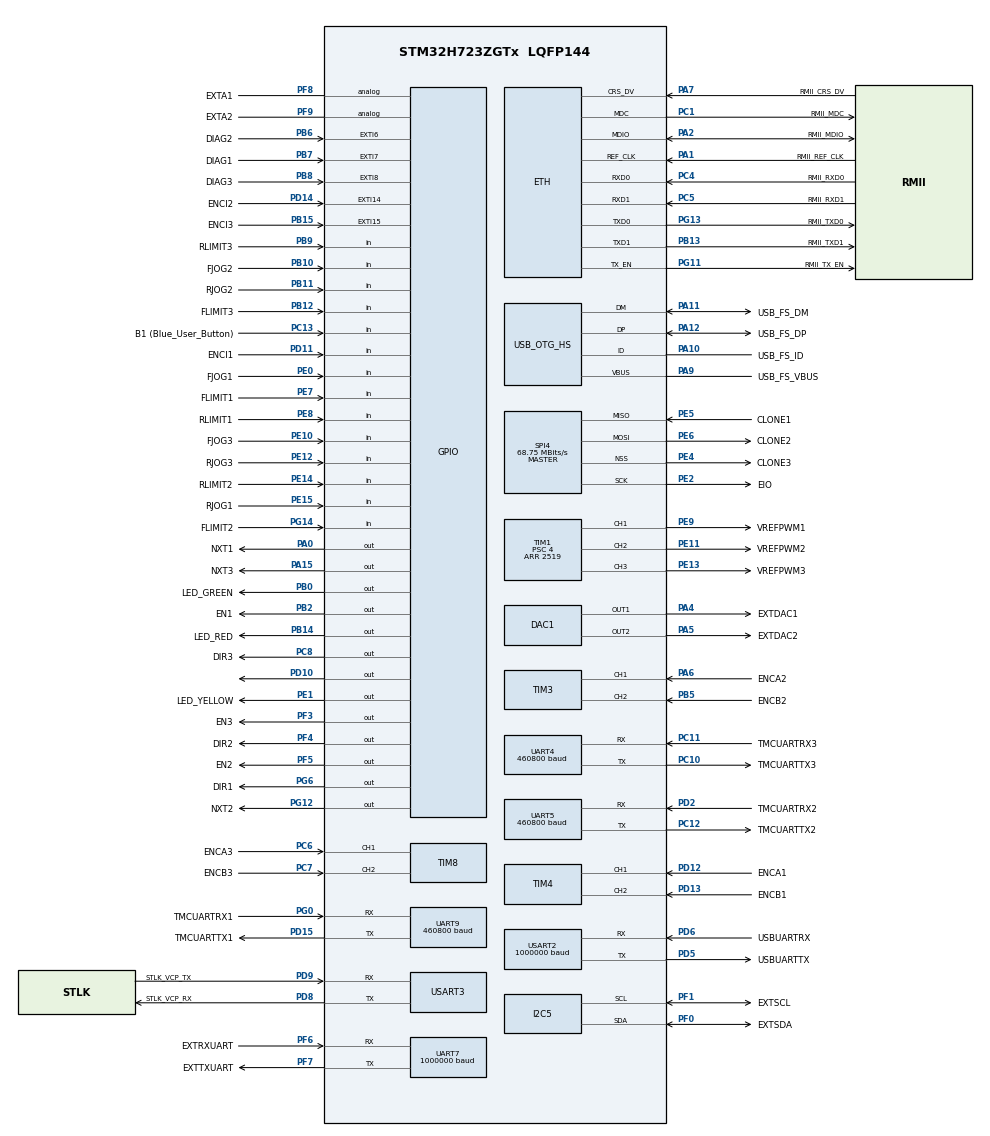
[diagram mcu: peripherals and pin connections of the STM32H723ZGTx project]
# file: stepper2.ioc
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DAC1.DAC_Channel-DAC_OUT1=DAC_CHANNEL_1
DAC1.DAC_Channel-DAC_OUT2=DAC_CHANNEL_2
Dma.Request0=USART2_RX
Dma.Request1=UART9_RX
Dma.Request2=UART5_RX
Dma.Request3=UART4_RX
Dma.UART4_RX.3.Direction=DMA_PERIPH_TO_MEMORY
Dma.UART4_RX.3.EventEnable=DISABLE
Dma.UART4_RX.3.FIFOMode=DMA_FIFOMODE_DISABLE
Dma.UART4_RX.3.Instance=DMA1_Stream3
Dma.UART4_RX.3.MemDataAlignment=DMA_MDATAALIGN_BYTE
Dma.UART4_RX.3.MemInc=DMA_MINC_ENABLE
Dma.UART4_RX.3.Mode=DMA_CIRCULAR
Dma.UART4_RX.3.PeriphDataAlignment=DMA_PDATAALIGN_BYTE
Dma.UART4_RX.3.PeriphInc=DMA_PINC_DISABLE
Dma.UART4_RX.3.Polarity=HAL_DMAMUX_REQ_GEN_RISING
Dma.UART4_RX.3.Priority=DMA_PRIORITY_LOW
Dma.UART4_RX.3.RequestNumber=1
Dma.UART4_RX.3.SignalID=NONE
Dma.UART4_RX.3.SyncEnable=DISABLE
Dma.UART4_RX.3.SyncPolarity=HAL_DMAMUX_SYNC_NO_EVENT
Dma.UART4_RX.3.SyncRequestNumber=1
Dma.UART4_RX.3.SyncSignalID=NONE
Dma.UART5_RX.2.Direction=DMA_PERIPH_TO_MEMORY
Dma.UART5_RX.2.EventEnable=DISABLE
Dma.UART5_RX.2.FIFOMode=DMA_FIFOMODE_DISABLE
Dma.UART5_RX.2.Instance=DMA1_Stream2
Dma.UART5_RX.2.MemDataAlignment=DMA_MDATAALIGN_BYTE
Dma.UART5_RX.2.MemInc=DMA_MINC_ENABLE
Dma.UART5_RX.2.Mode=DMA_CIRCULAR
Dma.UART5_RX.2.PeriphDataAlignment=DMA_PDATAALIGN_BYTE
Dma.UART5_RX.2.PeriphInc=DMA_PINC_DISABLE
Dma.UART5_RX.2.Polarity=HAL_DMAMUX_REQ_GEN_RISING
Dma.UART5_RX.2.Priority=DMA_PRIORITY_LOW
Dma.UART5_RX.2.RequestNumber=1
Dma.UART5_RX.2.SignalID=NONE
Dma.UART5_RX.2.SyncEnable=DISABLE
Dma.UART5_RX.2.SyncPolarity=HAL_DMAMUX_SYNC_NO_EVENT
Dma.UART5_RX.2.SyncRequestNumber=1
Dma.UART5_RX.2.SyncSignalID=NONE
Dma.UART9_RX.1.Direction=DMA_PERIPH_TO_MEMORY
Dma.UART9_RX.1.EventEnable=DISABLE
Dma.UART9_RX.1.FIFOMode=DMA_FIFOMODE_DISABLE
Dma.UART9_RX.1.Instance=DMA1_Stream1
Dma.UART9_RX.1.MemDataAlignment=DMA_MDATAALIGN_BYTE
Dma.UART9_RX.1.MemInc=DMA_MINC_ENABLE
Dma.UART9_RX.1.Mode=DMA_CIRCULAR
Dma.UART9_RX.1.PeriphDataAlignment=DMA_PDATAALIGN_BYTE
Dma.UART9_RX.1.PeriphInc=DMA_PINC_DISABLE
Dma.UART9_RX.1.Polarity=HAL_DMAMUX_REQ_GEN_RISING
Dma.UART9_RX.1.Priority=DMA_PRIORITY_LOW
Dma.UART9_RX.1.RequestNumber=1
Dma.UART9_RX.1.SignalID=NONE
Dma.UART9_RX.1.SyncEnable=DISABLE
Dma.UART9_RX.1.SyncPolarity=HAL_DMAMUX_SYNC_NO_EVENT
Dma.UART9_RX.1.SyncRequestNumber=1
Dma.UART9_RX.1.SyncSignalID=NONE
Dma.USART2_RX.0.Direction=DMA_PERIPH_TO_MEMORY
Dma.USART2_RX.0.EventEnable=DISABLE
Dma.USART2_RX.0.FIFOMode=DMA_FIFOMODE_DISABLE
Dma.USART2_RX.0.Instance=DMA1_Stream0
Dma.USART2_RX.0.MemDataAlignment=DMA_MDATAALIGN_BYTE
Dma.USART2_RX.0.MemInc=DMA_MINC_ENABLE
Dma.USART2_RX.0.Mode=DMA_CIRCULAR
Dma.USART2_RX.0.PeriphDataAlignment=DMA_PDATAALIGN_BYTE
Dma.USART2_RX.0.PeriphInc=DMA_PINC_DISABLE
Dma.USART2_RX.0.Polarity=HAL_DMAMUX_REQ_GEN_RISING
Dma.USART2_RX.0.Priority=DMA_PRIORITY_LOW
Dma.USART2_RX.0.RequestNumber=1
Dma.USART2_RX.0.SignalID=NONE
Dma.USART2_RX.0.SyncEnable=DISABLE
Dma.USART2_RX.0.SyncPolarity=HAL_DMAMUX_SYNC_NO_EVENT
Dma.USART2_RX.0.SyncRequestNumber=1
Dma.USART2_RX.0.SyncSignalID=NONE
ETH.MediaInterface=HAL_ETH_RMII_MODE
I2C5.Timing=0x60404E72
Mcu.Family=STM32H7
Mcu.Name=STM32H723ZGTx
Mcu.Package=LQFP144
NVIC.DMA1_Stream0_IRQn=true\:0\:0\:false\:false\:true\:false\:true\:true
NVIC.DMA1_Stream1_IRQn=true\:0\:0\:false\:false\:true\:false\:true\:true
NVIC.DMA1_Stream2_IRQn=true\:0\:0\:false\:false\:true\:false\:true\:true
NVIC.DMA1_Stream3_IRQn=true\:0\:0\:false\:false\:true\:false\:true\:true
NVIC.PriorityGroup=NVIC_PRIORITYGROUP_4
NVIC.TIM6_DAC_IRQn=true\:4\:0\:true\:false\:true\:true\:true\:true
NVIC.TIM7_IRQn=true\:2\:0\:true\:false\:true\:true\:true\:true
PA0.GPIO_Label=NXT1
PA0.Signal=GPIO_Output
PA1.GPIO_Label=RMII_REF_CLK
PA1.Mode=RMII
PA1.Signal=ETH_REF_CLK
PA10.GPIO_Label=USB_FS_ID
PA10.Mode=OTG/Dual-Role-Device-FS
PA10.Signal=USB_OTG_HS_ID
PA11.GPIO_Label=USB_FS_DM
PA11.Mode=OTG/Dual-Role-Device-FS
PA11.Signal=USB_OTG_HS_DM
PA12.GPIO_Label=USB_FS_DP
PA12.Mode=OTG/Dual-Role-Device-FS
PA12.Signal=USB_OTG_HS_DP
PA13(JTMS/SWDIO).GPIO_Label=SWDIO
PA13(JTMS/SWDIO).Mode=Trace_Asynchronous_SW
PA13(JTMS/SWDIO).Signal=DEBUG_JTMS-SWDIO
PA14(JTCK/SWCLK).GPIO_Label=SWCLK
PA14(JTCK/SWCLK).Mode=Trace_Asynchronous_SW
PA14(JTCK/SWCLK).Signal=DEBUG_JTCK-SWCLK
PA15(JTDI).GPIO_Label=NXT3
PA15(JTDI).Signal=GPIO_Output
PA2.GPIO_Label=RMII_MDIO
PA2.Mode=RMII
PA2.Signal=ETH_MDIO
PA4.GPIO_Label=EXTDAC1
PA4.Signal=COMP_DAC11_group
PA5.GPIO_Label=EXTDAC2
PA5.Signal=COMP_DAC12_group
PA6.GPIO_Label=ENCA2
PA6.Signal=S_TIM3_CH1
PA7.GPIO_Label=RMII_CRS_DV
PA7.Mode=RMII
PA7.Signal=ETH_CRS_DV
PA9.GPIO_Label=USB_FS_VBUS
PA9.Mode=Activate_VBUS_FS
PA9.Signal=USB_OTG_HS_VBUS
PB0.GPIO_Label=LED_GREEN
PB0.Signal=GPIO_Output
PB10.GPIO_Label=FJOG2
PB10.GPIO_PuPd=GPIO_PULLUP
PB10.Signal=GPIO_Input
PB11.GPIO_Label=RJOG2
PB11.GPIO_PuPd=GPIO_PULLUP
PB11.Signal=GPIO_Input
PB12.GPIO_Label=FLIMIT3
PB12.Signal=GPIO_Input
PB13.GPIO_Label=RMII_TXD1
PB13.Mode=RMII
PB13.Signal=ETH_TXD1
PB14.GPIO_Label=LED_RED
PB14.Signal=GPIO_Output
PB15.GPIO_Label=ENCI3
PB15.Signal=GPXTI15
PB2.GPIO_Label=EN1
PB2.Signal=GPIO_Output
PB3(JTDO/TRACESWO).GPIO_Label=SWO
PB3(JTDO/TRACESWO).Mode=Trace_Asynchronous_SW
PB3(JTDO/TRACESWO).Signal=DEBUG_JTDO-SWO
PB5.GPIO_Label=ENCB2
PB5.Signal=S_TIM3_CH2
PB6.GPIO_Label=DIAG2
PB6.Signal=GPXTI6
PB7.GPIO_Label=DIAG1
PB7.Signal=GPXTI7
PB8.GPIO_Label=DIAG3
PB8.Signal=GPXTI8
PB9.GPIO_Label=RLIMIT3
PB9.Signal=GPIO_Input
PC1.GPIO_Label=RMII_MDC
PC1.Mode=RMII
PC1.Signal=ETH_MDC
PC10.GPIO_Label=TMCUARTTX3
PC10.Mode=Asynchronous
PC10.Signal=UART4_TX
PC11.GPIO_Label=TMCUARTRX3
PC11.Mode=Asynchronous
PC11.Signal=UART4_RX
PC12.GPIO_Label=TMCUARTTX2
PC12.Mode=Asynchronous
PC12.Signal=UART5_TX
PC13.GPIO_Label=B1 (Blue_User_Button)
PC13.Signal=GPIO_Input
PC14-OSC32_IN.Mode=LSE-External-Oscillator
PC14-OSC32_IN.Signal=RCC_OSC32_IN
PC15-OSC32_OUT.Mode=LSE-External-Oscillator
PC15-OSC32_OUT.Signal=RCC_OSC32_OUT
PC4.GPIO_Label=RMII_RXD0
PC4.Mode=RMII
PC4.Signal=ETH_RXD0
PC5.GPIO_Label=RMII_RXD1
PC5.Mode=RMII
PC5.Signal=ETH_RXD1
PC6.GPIO_Label=ENCA3
PC6.Signal=S_TIM8_CH1
PC7.GPIO_Label=ENCB3
PC7.Signal=S_TIM8_CH2
PC8.GPIO_Label=DIR3
PC8.Signal=GPIO_Output
PD10.Signal=GPIO_Output
PD11.GPIO_Label=ENCI1
PD11.Signal=GPIO_Input
PD12.GPIO_Label=ENCA1
PD12.Signal=S_TIM4_CH1
PD13.GPIO_Label=ENCB1
PD13.Signal=S_TIM4_CH2
PD14.GPIO_Label=ENCI2
PD14.Signal=GPXTI14
PD15.GPIO_Label=TMCUARTTX1
PD15.Mode=Asynchronous
PD15.Signal=UART9_TX
PD2.GPIO_Label=TMCUARTRX2
PD2.GPIO_PuPd=GPIO_NOPULL
PD2.Mode=Asynchronous
PD2.Signal=UART5_RX
PD5.GPIO_Label=USBUARTTX
PD5.Mode=Asynchronous
PD5.Signal=USART2_TX
PD6.GPIO_Label=USBUARTRX
PD6.Mode=Asynchronous
PD6.Signal=USART2_RX
PD8.GPIO_Label=STLK_VCP_RX
PD8.Mode=Asynchronous
PD8.Signal=USART3_TX
PD9.GPIO_Label=STLK_VCP_TX
PD9.Mode=Asynchronous
PD9.Signal=USART3_RX
PE0.GPIO_Label=FJOG1
PE0.GPIO_PuPd=GPIO_PULLUP
PE0.Signal=GPIO_Input
PE1.GPIO_Label=LED_YELLOW
PE1.Signal=GPIO_Output
PE10.GPIO_Label=FJOG3
PE10.GPIO_PuPd=GPIO_PULLUP
PE10.Signal=GPIO_Input
PE11.GPIO_Label=VREFPWM2
PE11.Signal=S_TIM1_CH2
PE12.GPIO_Label=RJOG3
PE12.GPIO_PuPd=GPIO_PULLUP
PE12.Signal=GPIO_Input
PE13.GPIO_Label=VREFPWM3
PE13.Signal=S_TIM1_CH3
PE14.GPIO_Label=RLIMIT2
PE14.Signal=GPIO_Input
PE15.GPIO_Label=RJOG1
PE15.GPIO_PuPd=GPIO_PULLUP
PE15.Signal=GPIO_Input
PE2.GPIO_Label=EIO
PE2.Mode=Full_Duplex_Master
PE2.Signal=SPI4_SCK
PE4.GPIO_Label=CLONE3
PE4.Mode=NSS_Signal_Hard_Output
PE4.Signal=SPI4_NSS
PE5.GPIO_Label=CLONE1
PE5.Mode=Full_Duplex_Master
PE5.Signal=SPI4_MISO
PE6.GPIO_Label=CLONE2
PE6.Mode=Full_Duplex_Master
PE6.Signal=SPI4_MOSI
PE7.GPIO_Label=FLIMIT1
PE7.Signal=GPIO_Input
PE8.GPIO_Label=RLIMIT1
PE8.Signal=GPIO_Input
PE9.GPIO_Label=VREFPWM1
PE9.Signal=S_TIM1_CH1
PF0.GPIO_Label=EXTSDA
PF0.Mode=I2C
PF0.Signal=I2C5_SDA
PF1.GPIO_Label=EXTSCL
PF1.Mode=I2C
PF1.Signal=I2C5_SCL
PF3.GPIO_Label=EN3
PF3.Signal=GPIO_Output
PF4.GPIO_Label=DIR2
PF4.Signal=GPIO_Output
PF5.GPIO_Label=EN2
PF5.Signal=GPIO_Output
PF6.GPIO_Label=EXTRXUART
PF6.Mode=Asynchronous
PF6.Signal=UART7_RX
PF7.GPIO_Label=EXTTXUART
PF7.Mode=Asynchronous
PF7.Signal=UART7_TX
PF8.GPIO_Label=EXTA1
PF8.Signal=GPIO_Analog
PF9.GPIO_Label=EXTA2
PF9.Signal=GPIO_Analog
PG0.GPIO_Label=TMCUARTRX1
PG0.Mode=Asynchronous
PG0.Signal=UART9_RX
PG11.GPIO_Label=RMII_TX_EN
PG11.Mode=RMII
PG11.Signal=ETH_TX_EN
PG12.GPIO_Label=NXT2
PG12.Signal=GPIO_Output
PG13.GPIO_Label=RMII_TXD0
PG13.Mode=RMII
PG13.Signal=ETH_TXD0
PG14.GPIO_Label=FLIMIT2
PG14.Signal=GPIO_Input
PG6.GPIO_Label=DIR1
PG6.Signal=GPIO_Output
PH0-OSC_IN.GPIO_Label=MCO
PH0-OSC_IN.Mode=HSE-External-Clock-Source
PH0-OSC_IN.Signal=RCC_OSC_IN
PH1-OSC_OUT.Signal=RCC_OSC_OUT
ProjectManager.HeapSize=0x200
ProjectManager.StackSize=0x400
ProjectManager.TargetToolchain=STM32CubeIDE
RCC.ADCFreq_Value=76000000
RCC.APB1Freq_Value=137500000
RCC.APB2Freq_Value=137500000
RCC.APB3Freq_Value=137500000
RCC.APB4Freq_Value=137500000
RCC.CortexFreq_Value=550000000
RCC.D1PPRE=RCC_APB3_DIV2
RCC.D2PPRE1=RCC_APB1_DIV2
RCC.D2PPRE2=RCC_APB2_DIV2
RCC.D3PPRE=RCC_APB4_DIV2
RCC.DIVM1=4
RCC.DIVM2=1
RCC.DIVN1=275
RCC.DIVN2=19
RCC.DIVP1=1
RCC.DIVQ1=4
RCC.HCLKFreq_Value=275000000
RCC.HPRE=RCC_HCLK_DIV2
RCC.HSE_VALUE=8000000
RCC.PLLFRACN=0
RCC.PLLSourceVirtual=RCC_PLLSOURCE_HSE
RCC.SYSCLKFreq_VALUE=550000000
RCC.SYSCLKSource=RCC_SYSCLKSOURCE_PLLCLK
RCC.USBCLockSelection=RCC_USBCLKSOURCE_HSI48
RCC.USBFreq_Value=48000000
SH.COMP_DAC11_group.0=DAC1_OUT1,DAC_OUT1
SH.COMP_DAC12_group.0=DAC1_OUT2,DAC_OUT2
SH.S_TIM1_CH1.0=TIM1_CH1,PWM Generation1 CH1
SH.S_TIM1_CH2.0=TIM1_CH2,PWM Generation2 CH2
SH.S_TIM1_CH3.0=TIM1_CH3,PWM Generation3 CH3
SH.S_TIM3_CH1.0=TIM3_CH1,Encoder_Interface
SH.S_TIM3_CH2.0=TIM3_CH2,Encoder_Interface
SH.S_TIM4_CH1.0=TIM4_CH1,Encoder_Interface
SH.S_TIM4_CH2.0=TIM4_CH2,Encoder_Interface
SH.S_TIM8_CH1.0=TIM8_CH1,Encoder_Interface
SH.S_TIM8_CH2.0=TIM8_CH2,Encoder_Interface
SPI4.CalculateBaudRate=68.75 MBits/s
SPI4.Direction=SPI_DIRECTION_2LINES
SPI4.Mode=SPI_MODE_MASTER
SPI4.VirtualNSS=VM_NSSHARD
SPI4.VirtualType=VM_MASTER
TIM1.AutoReloadPreload=TIM_AUTORELOAD_PRELOAD_ENABLE
TIM1.Channel-PWM\ Generation1\ CH1=TIM_CHANNEL_1
TIM1.Channel-PWM\ Generation2\ CH2=TIM_CHANNEL_2
TIM1.Channel-PWM\ Generation3\ CH3=TIM_CHANNEL_3
TIM1.Period=2519
TIM1.Prescaler=4
TIM24.Period=0xffffffff
TIM24.Prescaler=274
TIM3.EncoderMode=TIM_ENCODERMODE_TI12
TIM4.EncoderMode=TIM_ENCODERMODE_TI12
TIM6.AutoReloadPreload=TIM_AUTORELOAD_PRELOAD_DISABLE
TIM6.Period=999
TIM6.Prescaler=274
TIM7.AutoReloadPreload=TIM_AUTORELOAD_PRELOAD_DISABLE
TIM7.Period=1759
TIM8.EncoderMode=TIM_ENCODERMODE_TI12
UART4.BaudRate=460800
UART5.BaudRate=460800
UART7.BaudRate=1000000
UART9.BaudRate=460800
USART2.BaudRate=1000000
USART2.VirtualMode-Asynchronous=VM_ASYNC
USART3.VirtualMode-Asynchronous=VM_ASYNC
VP_TIM1_VS_ClockSourceINT.Mode=Internal
VP_TIM24_VS_ClockSourceINT.Mode=Internal
VP_TIM6_VS_ClockSourceINT.Mode=Enable_Timer
VP_TIM7_VS_ClockSourceINT.Mode=Enable_Timer
board=NUCLEO-H723ZG

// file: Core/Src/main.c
/* USER CODE BEGIN Header */
/**
  ******************************************************************************
  * @file           : main.c
  * @brief          : Main program body
  ******************************************************************************
  * @attention
  *
  * Copyright (c) 2023 STMicroelectronics.
  * All rights reserved.
  *
  * This software is licensed under terms that can be found in the LICENSE file
  * in the root directory of this software component.
  * If no LICENSE file comes with this software, it is provided AS-IS.
  *
  ******************************************************************************
  */
/* USER CODE END Header */
#include "main.h"
#include "string.h"

/* USER CODE BEGIN Includes */

#include "usr_main.hpp"
#include "handles.hpp"
/* USER CODE END Includes */

#if defined ( __ICCARM__ ) /*!< IAR Compiler */
#pragma location=0x30000000
ETH_DMADescTypeDef  DMARxDscrTab[ETH_RX_DESC_CNT]; /* Ethernet Rx DMA Descriptors */
#pragma location=0x30000200
ETH_DMADescTypeDef  DMATxDscrTab[ETH_TX_DESC_CNT]; /* Ethernet Tx DMA Descriptors */

#elif defined ( __CC_ARM )  /* MDK ARM Compiler */

__attribute__((at(0x30000000))) ETH_DMADescTypeDef  DMARxDscrTab[ETH_RX_DESC_CNT]; /* Ethernet Rx DMA Descriptors */
__attribute__((at(0x30000200))) ETH_DMADescTypeDef  DMATxDscrTab[ETH_TX_DESC_CNT]; /* Ethernet Tx DMA Descriptors */

#elif defined ( __GNUC__ ) /* GNU Compiler */
ETH_DMADescTypeDef DMARxDscrTab[ETH_RX_DESC_CNT] __attribute__((section(".RxDecripSection"))); /* Ethernet Rx DMA Descriptors */
ETH_DMADescTypeDef DMATxDscrTab[ETH_TX_DESC_CNT] __attribute__((section(".TxDecripSection")));   /* Ethernet Tx DMA Descriptors */

#endif

ETH_TxPacketConfig TxConfig;

DAC_HandleTypeDef hdac1;

ETH_HandleTypeDef heth;

I2C_HandleTypeDef hi2c5;

SPI_HandleTypeDef hspi4;

TIM_HandleTypeDef htim1;
TIM_HandleTypeDef htim3;
TIM_HandleTypeDef htim4;
TIM_HandleTypeDef htim6;
TIM_HandleTypeDef htim7;
TIM_HandleTypeDef htim8;
TIM_HandleTypeDef htim24;

UART_HandleTypeDef huart4;
UART_HandleTypeDef huart5;
UART_HandleTypeDef huart7;
UART_HandleTypeDef huart9;
UART_HandleTypeDef huart2;
UART_HandleTypeDef huart3;
DMA_HandleTypeDef hdma_uart4_rx;
DMA_HandleTypeDef hdma_uart5_rx;
DMA_HandleTypeDef hdma_uart9_rx;
DMA_HandleTypeDef hdma_usart2_rx;

void SystemClock_Config(void);
static void MX_GPIO_Init(void);
static void MX_DMA_Init(void);
static void MX_USART3_UART_Init(void);
static void MX_USB_OTG_HS_USB_Init(void);
static void MX_TIM1_Init(void);
static void MX_TIM3_Init(void);
static void MX_TIM4_Init(void);
static void MX_TIM8_Init(void);
static void MX_UART4_Init(void);
static void MX_UART5_Init(void);
static void MX_UART7_Init(void);
static void MX_USART2_UART_Init(void);
static void MX_DAC1_Init(void);
static void MX_I2C5_Init(void);
static void MX_SPI4_Init(void);
static void MX_UART9_Init(void);
static void MX_ETH_Init(void);
static void MX_TIM24_Init(void);
static void MX_TIM6_Init(void);
static void MX_TIM7_Init(void);

int main(void)
{

  /* MCU Configuration--------------------------------------------------------*/

  /* Reset of all peripherals, Initializes the Flash interface and the Systick. */
  HAL_Init();

  /* Configure the system clock */
  SystemClock_Config();

  /* Initialize all configured peripherals */
  MX_GPIO_Init();
  MX_DMA_Init();
  MX_USART3_UART_Init();
  MX_USB_OTG_HS_USB_Init();
  MX_TIM1_Init();
  MX_TIM3_Init();
  MX_TIM4_Init();
  MX_TIM8_Init();
  MX_UART4_Init();
  MX_UART5_Init();
  MX_UART7_Init();
  MX_USART2_UART_Init();
  MX_DAC1_Init();
  MX_I2C5_Init();
  MX_SPI4_Init();
  MX_UART9_Init();
  MX_ETH_Init();
  MX_TIM24_Init();
  MX_TIM6_Init();
  MX_TIM7_Init();

  /* Infinite loop */
  /* USER CODE BEGIN WHILE */
  usr_main();
    /* USER CODE END WHILE */

}

void SystemClock_Config(void)
{
  RCC_OscInitTypeDef RCC_OscInitStruct = {0};
  RCC_ClkInitTypeDef RCC_ClkInitStruct = {0};

  /** Supply configuration update enable
  */
  HAL_PWREx_ConfigSupply(PWR_LDO_SUPPLY);

  /** Configure the main internal regulator output voltage
  */
  __HAL_PWR_VOLTAGESCALING_CONFIG(PWR_REGULATOR_VOLTAGE_SCALE0);

  while(!__HAL_PWR_GET_FLAG(PWR_FLAG_VOSRDY)) {}

  /** Initializes the RCC Oscillators according to the specified parameters
  * in the RCC_OscInitTypeDef structure.
  */
  RCC_OscInitStruct.OscillatorType = RCC_OSCILLATORTYPE_HSI48|RCC_OSCILLATORTYPE_HSE;
  RCC_OscInitStruct.HSEState = RCC_HSE_BYPASS;
  RCC_OscInitStruct.HSI48State = RCC_HSI48_ON;
  RCC_OscInitStruct.PLL.PLLState = RCC_PLL_ON;
  RCC_OscInitStruct.PLL.PLLSource = RCC_PLLSOURCE_HSE;
  RCC_OscInitStruct.PLL.PLLM = 4;
  RCC_OscInitStruct.PLL.PLLN = 275;
  RCC_OscInitStruct.PLL.PLLP = 1;
  RCC_OscInitStruct.PLL.PLLQ = 4;
  RCC_OscInitStruct.PLL.PLLR = 2;
  RCC_OscInitStruct.PLL.PLLRGE = RCC_PLL1VCIRANGE_1;
  RCC_OscInitStruct.PLL.PLLVCOSEL = RCC_PLL1VCOWIDE;
  RCC_OscInitStruct.PLL.PLLFRACN = 0;
  if (HAL_RCC_OscConfig(&RCC_OscInitStruct) != HAL_OK)
  {
    Error_Handler();
  }

  /** Initializes the CPU, AHB and APB buses clocks
  */
  RCC_ClkInitStruct.ClockType = RCC_CLOCKTYPE_HCLK|RCC_CLOCKTYPE_SYSCLK
                              |RCC_CLOCKTYPE_PCLK1|RCC_CLOCKTYPE_PCLK2
                              |RCC_CLOCKTYPE_D3PCLK1|RCC_CLOCKTYPE_D1PCLK1;
  RCC_ClkInitStruct.SYSCLKSource = RCC_SYSCLKSOURCE_PLLCLK;
  RCC_ClkInitStruct.SYSCLKDivider = RCC_SYSCLK_DIV1;
  RCC_ClkInitStruct.AHBCLKDivider = RCC_HCLK_DIV2;
  RCC_ClkInitStruct.APB3CLKDivider = RCC_APB3_DIV2;
  RCC_ClkInitStruct.APB1CLKDivider = RCC_APB1_DIV2;
  RCC_ClkInitStruct.APB2CLKDivider = RCC_APB2_DIV2;
  RCC_ClkInitStruct.APB4CLKDivider = RCC_APB4_DIV2;

  if (HAL_RCC_ClockConfig(&RCC_ClkInitStruct, FLASH_LATENCY_3) != HAL_OK)
  {
    Error_Handler();
  }
}

static void MX_DAC1_Init(void)
{

  DAC_ChannelConfTypeDef sConfig = {0};

  /** DAC Initialization
  */
  hdac1.Instance = DAC1;
  if (HAL_DAC_Init(&hdac1) != HAL_OK)
  {
    Error_Handler();
  }

  /** DAC channel OUT1 config
  */
  sConfig.DAC_SampleAndHold = DAC_SAMPLEANDHOLD_DISABLE;
  sConfig.DAC_Trigger = DAC_TRIGGER_NONE;
  sConfig.DAC_OutputBuffer = DAC_OUTPUTBUFFER_ENABLE;
  sConfig.DAC_ConnectOnChipPeripheral = DAC_CHIPCONNECT_DISABLE;
  sConfig.DAC_UserTrimming = DAC_TRIMMING_FACTORY;
  if (HAL_DAC_ConfigChannel(&hdac1, &sConfig, DAC_CHANNEL_1) != HAL_OK)
  {
    Error_Handler();
  }

  /** DAC channel OUT2 config
  */
  if (HAL_DAC_ConfigChannel(&hdac1, &sConfig, DAC_CHANNEL_2) != HAL_OK)
  {
    Error_Handler();
  }

}

static void MX_ETH_Init(void)
{

   static uint8_t MACAddr[6];

  heth.Instance = ETH;
  MACAddr[0] = 0x00;
  MACAddr[1] = 0x80;
  MACAddr[2] = 0xE1;
  MACAddr[3] = 0x00;
  MACAddr[4] = 0x00;
  MACAddr[5] = 0x00;
  heth.Init.MACAddr = &MACAddr[0];
  heth.Init.MediaInterface = HAL_ETH_RMII_MODE;
  heth.Init.TxDesc = DMATxDscrTab;
  heth.Init.RxDesc = DMARxDscrTab;
  heth.Init.RxBuffLen = 1524;

  if (HAL_ETH_Init(&heth) != HAL_OK)
  {
    Error_Handler();
  }

  memset(&TxConfig, 0 , sizeof(ETH_TxPacketConfig));
  TxConfig.Attributes = ETH_TX_PACKETS_FEATURES_CSUM | ETH_TX_PACKETS_FEATURES_CRCPAD;
  TxConfig.ChecksumCtrl = ETH_CHECKSUM_IPHDR_PAYLOAD_INSERT_PHDR_CALC;
  TxConfig.CRCPadCtrl = ETH_CRC_PAD_INSERT;

}

static void MX_I2C5_Init(void)
{

  hi2c5.Instance = I2C5;
  hi2c5.Init.Timing = 0x60404E72;
  hi2c5.Init.OwnAddress1 = 0;
  hi2c5.Init.AddressingMode = I2C_ADDRESSINGMODE_7BIT;
  hi2c5.Init.DualAddressMode = I2C_DUALADDRESS_DISABLE;
  hi2c5.Init.OwnAddress2 = 0;
  hi2c5.Init.OwnAddress2Masks = I2C_OA2_NOMASK;
  hi2c5.Init.GeneralCallMode = I2C_GENERALCALL_DISABLE;
  hi2c5.Init.NoStretchMode = I2C_NOSTRETCH_DISABLE;
  if (HAL_I2C_Init(&hi2c5) != HAL_OK)
  {
    Error_Handler();
  }

  /** Configure Analogue filter
  */
  if (HAL_I2CEx_ConfigAnalogFilter(&hi2c5, I2C_ANALOGFILTER_ENABLE) != HAL_OK)
  {
    Error_Handler();
  }

  /** Configure Digital filter
  */
  if (HAL_I2CEx_ConfigDigitalFilter(&hi2c5, 0) != HAL_OK)
  {
    Error_Handler();
  }

}

static void MX_SPI4_Init(void)
{

  /* SPI4 parameter configuration*/
  hspi4.Instance = SPI4;
  hspi4.Init.Mode = SPI_MODE_MASTER;
  hspi4.Init.Direction = SPI_DIRECTION_2LINES;
  hspi4.Init.DataSize = SPI_DATASIZE_4BIT;
  hspi4.Init.CLKPolarity = SPI_POLARITY_LOW;
  hspi4.Init.CLKPhase = SPI_PHASE_1EDGE;
  hspi4.Init.NSS = SPI_NSS_HARD_OUTPUT;
  hspi4.Init.BaudRatePrescaler = SPI_BAUDRATEPRESCALER_2;
  hspi4.Init.FirstBit = SPI_FIRSTBIT_MSB;
  hspi4.Init.TIMode = SPI_TIMODE_DISABLE;
  hspi4.Init.CRCCalculation = SPI_CRCCALCULATION_DISABLE;
  hspi4.Init.CRCPolynomial = 0x0;
  hspi4.Init.NSSPMode = SPI_NSS_PULSE_ENABLE;
  hspi4.Init.NSSPolarity = SPI_NSS_POLARITY_LOW;
  hspi4.Init.FifoThreshold = SPI_FIFO_THRESHOLD_01DATA;
  hspi4.Init.TxCRCInitializationPattern = SPI_CRC_INITIALIZATION_ALL_ZERO_PATTERN;
  hspi4.Init.RxCRCInitializationPattern = SPI_CRC_INITIALIZATION_ALL_ZERO_PATTERN;
  hspi4.Init.MasterSSIdleness = SPI_MASTER_SS_IDLENESS_00CYCLE;
  hspi4.Init.MasterInterDataIdleness = SPI_MASTER_INTERDATA_IDLENESS_00CYCLE;
  hspi4.Init.MasterReceiverAutoSusp = SPI_MASTER_RX_AUTOSUSP_DISABLE;
  hspi4.Init.MasterKeepIOState = SPI_MASTER_KEEP_IO_STATE_DISABLE;
  hspi4.Init.IOSwap = SPI_IO_SWAP_DISABLE;
  if (HAL_SPI_Init(&hspi4) != HAL_OK)
  {
    Error_Handler();
  }

}

static void MX_TIM1_Init(void)
{

  TIM_ClockConfigTypeDef sClockSourceConfig = {0};
  TIM_MasterConfigTypeDef sMasterConfig = {0};
  TIM_OC_InitTypeDef sConfigOC = {0};
  TIM_BreakDeadTimeConfigTypeDef sBreakDeadTimeConfig = {0};

  htim1.Instance = TIM1;
  htim1.Init.Prescaler = 4;
  htim1.Init.CounterMode = TIM_COUNTERMODE_UP;
  htim1.Init.Period = 2519;
  htim1.Init.ClockDivision = TIM_CLOCKDIVISION_DIV1;
  htim1.Init.RepetitionCounter = 0;
  htim1.Init.AutoReloadPreload = TIM_AUTORELOAD_PRELOAD_ENABLE;
  if (HAL_TIM_Base_Init(&htim1) != HAL_OK)
  {
    Error_Handler();
  }
  sClockSourceConfig.ClockSource = TIM_CLOCKSOURCE_INTERNAL;
  if (HAL_TIM_ConfigClockSource(&htim1, &sClockSourceConfig) != HAL_OK)
  {
    Error_Handler();
  }
  if (HAL_TIM_PWM_Init(&htim1) != HAL_OK)
  {
    Error_Handler();
  }
  sMasterConfig.MasterOutputTrigger = TIM_TRGO_RESET;
  sMasterConfig.MasterOutputTrigger2 = TIM_TRGO2_RESET;
  sMasterConfig.MasterSlaveMode = TIM_MASTERSLAVEMODE_DISABLE;
  if (HAL_TIMEx_MasterConfigSynchronization(&htim1, &sMasterConfig) != HAL_OK)
  {
    Error_Handler();
  }
  sConfigOC.OCMode = TIM_OCMODE_PWM1;
  sConfigOC.Pulse = 0;
  sConfigOC.OCPolarity = TIM_OCPOLARITY_HIGH;
  sConfigOC.OCNPolarity = TIM_OCNPOLARITY_HIGH;
  sConfigOC.OCFastMode = TIM_OCFAST_DISABLE;
  sConfigOC.OCIdleState = TIM_OCIDLESTATE_RESET;
  sConfigOC.OCNIdleState = TIM_OCNIDLESTATE_RESET;
  if (HAL_TIM_PWM_ConfigChannel(&htim1, &sConfigOC, TIM_CHANNEL_1) != HAL_OK)
  {
    Error_Handler();
  }
  if (HAL_TIM_PWM_ConfigChannel(&htim1, &sConfigOC, TIM_CHANNEL_2) != HAL_OK)
  {
    Error_Handler();
  }
  if (HAL_TIM_PWM_ConfigChannel(&htim1, &sConfigOC, TIM_CHANNEL_3) != HAL_OK)
  {
    Error_Handler();
  }
  sBreakDeadTimeConfig.OffStateRunMode = TIM_OSSR_DISABLE;
  sBreakDeadTimeConfig.OffStateIDLEMode = TIM_OSSI_DISABLE;
  sBreakDeadTimeConfig.LockLevel = TIM_LOCKLEVEL_OFF;
  sBreakDeadTimeConfig.DeadTime = 0;
  sBreakDeadTimeConfig.BreakState = TIM_BREAK_DISABLE;
  sBreakDeadTimeConfig.BreakPolarity = TIM_BREAKPOLARITY_HIGH;
  sBreakDeadTimeConfig.BreakFilter = 0;
  sBreakDeadTimeConfig.Break2State = TIM_BREAK2_DISABLE;
  sBreakDeadTimeConfig.Break2Polarity = TIM_BREAK2POLARITY_HIGH;
  sBreakDeadTimeConfig.Break2Filter = 0;
  sBreakDeadTimeConfig.AutomaticOutput = TIM_AUTOMATICOUTPUT_DISABLE;
  if (HAL_TIMEx_ConfigBreakDeadTime(&htim1, &sBreakDeadTimeConfig) != HAL_OK)
  {
    Error_Handler();
  }
  HAL_TIM_MspPostInit(&htim1);

}

static void MX_TIM3_Init(void)
{

  TIM_Encoder_InitTypeDef sConfig = {0};
  TIM_MasterConfigTypeDef sMasterConfig = {0};

  htim3.Instance = TIM3;
  htim3.Init.Prescaler = 0;
  htim3.Init.CounterMode = TIM_COUNTERMODE_UP;
  htim3.Init.Period = 65535;
  htim3.Init.ClockDivision = TIM_CLOCKDIVISION_DIV1;
  htim3.Init.AutoReloadPreload = TIM_AUTORELOAD_PRELOAD_DISABLE;
  sConfig.EncoderMode = TIM_ENCODERMODE_TI12;
  sConfig.IC1Polarity = TIM_ICPOLARITY_RISING;
  sConfig.IC1Selection = TIM_ICSELECTION_DIRECTTI;
  sConfig.IC1Prescaler = TIM_ICPSC_DIV1;
  sConfig.IC1Filter = 0;
  sConfig.IC2Polarity = TIM_ICPOLARITY_RISING;
  sConfig.IC2Selection = TIM_ICSELECTION_DIRECTTI;
  sConfig.IC2Prescaler = TIM_ICPSC_DIV1;
  sConfig.IC2Filter = 0;
  if (HAL_TIM_Encoder_Init(&htim3, &sConfig) != HAL_OK)
  {
    Error_Handler();
  }
  sMasterConfig.MasterOutputTrigger = TIM_TRGO_RESET;
  sMasterConfig.MasterSlaveMode = TIM_MASTERSLAVEMODE_DISABLE;
  if (HAL_TIMEx_MasterConfigSynchronization(&htim3, &sMasterConfig) != HAL_OK)
  {
    Error_Handler();
  }

}

static void MX_TIM4_Init(void)
{

  TIM_Encoder_InitTypeDef sConfig = {0};
  TIM_MasterConfigTypeDef sMasterConfig = {0};

  htim4.Instance = TIM4;
  htim4.Init.Prescaler = 0;
  htim4.Init.CounterMode = TIM_COUNTERMODE_UP;
  htim4.Init.Period = 65535;
  htim4.Init.ClockDivision = TIM_CLOCKDIVISION_DIV1;
  htim4.Init.AutoReloadPreload = TIM_AUTORELOAD_PRELOAD_DISABLE;
  sConfig.EncoderMode = TIM_ENCODERMODE_TI12;
  sConfig.IC1Polarity = TIM_ICPOLARITY_RISING;
  sConfig.IC1Selection = TIM_ICSELECTION_DIRECTTI;
  sConfig.IC1Prescaler = TIM_ICPSC_DIV1;
  sConfig.IC1Filter = 0;
  sConfig.IC2Polarity = TIM_ICPOLARITY_RISING;
  sConfig.IC2Selection = TIM_ICSELECTION_DIRECTTI;
  sConfig.IC2Prescaler = TIM_ICPSC_DIV1;
  sConfig.IC2Filter = 0;
  if (HAL_TIM_Encoder_Init(&htim4, &sConfig) != HAL_OK)
  {
    Error_Handler();
  }
  sMasterConfig.MasterOutputTrigger = TIM_TRGO_RESET;
  sMasterConfig.MasterSlaveMode = TIM_MASTERSLAVEMODE_DISABLE;
  if (HAL_TIMEx_MasterConfigSynchronization(&htim4, &sMasterConfig) != HAL_OK)
  {
    Error_Handler();
  }

}

static void MX_TIM6_Init(void)
{

  TIM_MasterConfigTypeDef sMasterConfig = {0};

  htim6.Instance = TIM6;
  htim6.Init.Prescaler = 274;
  htim6.Init.CounterMode = TIM_COUNTERMODE_UP;
  htim6.Init.Period = 999;
  htim6.Init.AutoReloadPreload = TIM_AUTORELOAD_PRELOAD_DISABLE;
  if (HAL_TIM_Base_Init(&htim6) != HAL_OK)
  {
    Error_Handler();
  }
  sMasterConfig.MasterOutputTrigger = TIM_TRGO_RESET;
  sMasterConfig.MasterSlaveMode = TIM_MASTERSLAVEMODE_DISABLE;
  if (HAL_TIMEx_MasterConfigSynchronization(&htim6, &sMasterConfig) != HAL_OK)
  {
    Error_Handler();
  }

}

static void MX_TIM7_Init(void)
{

  TIM_MasterConfigTypeDef sMasterConfig = {0};

  htim7.Instance = TIM7;
  htim7.Init.Prescaler = 0;
  htim7.Init.CounterMode = TIM_COUNTERMODE_UP;
  htim7.Init.Period = 1759;
  htim7.Init.AutoReloadPreload = TIM_AUTORELOAD_PRELOAD_DISABLE;
  if (HAL_TIM_Base_Init(&htim7) != HAL_OK)
  {
    Error_Handler();
  }
  sMasterConfig.MasterOutputTrigger = TIM_TRGO_RESET;
  sMasterConfig.MasterSlaveMode = TIM_MASTERSLAVEMODE_DISABLE;
  if (HAL_TIMEx_MasterConfigSynchronization(&htim7, &sMasterConfig) != HAL_OK)
  {
    Error_Handler();
  }

}

static void MX_TIM8_Init(void)
{

  TIM_Encoder_InitTypeDef sConfig = {0};
  TIM_MasterConfigTypeDef sMasterConfig = {0};

  htim8.Instance = TIM8;
  htim8.Init.Prescaler = 0;
  htim8.Init.CounterMode = TIM_COUNTERMODE_UP;
  htim8.Init.Period = 65535;
  htim8.Init.ClockDivision = TIM_CLOCKDIVISION_DIV1;
  htim8.Init.RepetitionCounter = 0;
  htim8.Init.AutoReloadPreload = TIM_AUTORELOAD_PRELOAD_DISABLE;
  sConfig.EncoderMode = TIM_ENCODERMODE_TI12;
  sConfig.IC1Polarity = TIM_ICPOLARITY_RISING;
  sConfig.IC1Selection = TIM_ICSELECTION_DIRECTTI;
  sConfig.IC1Prescaler = TIM_ICPSC_DIV1;
  sConfig.IC1Filter = 0;
  sConfig.IC2Polarity = TIM_ICPOLARITY_RISING;
  sConfig.IC2Selection = TIM_ICSELECTION_DIRECTTI;
  sConfig.IC2Prescaler = TIM_ICPSC_DIV1;
  sConfig.IC2Filter = 0;
  if (HAL_TIM_Encoder_Init(&htim8, &sConfig) != HAL_OK)
  {
    Error_Handler();
  }
  sMasterConfig.MasterOutputTrigger = TIM_TRGO_RESET;
  sMasterConfig.MasterOutputTrigger2 = TIM_TRGO2_RESET;
  sMasterConfig.MasterSlaveMode = TIM_MASTERSLAVEMODE_DISABLE;
  if (HAL_TIMEx_MasterConfigSynchronization(&htim8, &sMasterConfig) != HAL_OK)
  {
    Error_Handler();
  }

}

static void MX_TIM24_Init(void)
{

  TIM_ClockConfigTypeDef sClockSourceConfig = {0};
  TIM_MasterConfigTypeDef sMasterConfig = {0};

  htim24.Instance = TIM24;
  htim24.Init.Prescaler = 274;
  htim24.Init.CounterMode = TIM_COUNTERMODE_UP;
  htim24.Init.Period = 0xffffffff;
  htim24.Init.ClockDivision = TIM_CLOCKDIVISION_DIV1;
  htim24.Init.AutoReloadPreload = TIM_AUTORELOAD_PRELOAD_DISABLE;
  if (HAL_TIM_Base_Init(&htim24) != HAL_OK)
  {
    Error_Handler();
  }
  sClockSourceConfig.ClockSource = TIM_CLOCKSOURCE_INTERNAL;
  if (HAL_TIM_ConfigClockSource(&htim24, &sClockSourceConfig) != HAL_OK)
  {
    Error_Handler();
  }
  sMasterConfig.MasterOutputTrigger = TIM_TRGO_RESET;
  sMasterConfig.MasterSlaveMode = TIM_MASTERSLAVEMODE_DISABLE;
  if (HAL_TIMEx_MasterConfigSynchronization(&htim24, &sMasterConfig) != HAL_OK)
  {
    Error_Handler();
  }

}

static void MX_UART4_Init(void)
{

  huart4.Instance = UART4;
  huart4.Init.BaudRate = 460800;
  huart4.Init.WordLength = UART_WORDLENGTH_8B;
  huart4.Init.StopBits = UART_STOPBITS_1;
  huart4.Init.Parity = UART_PARITY_NONE;
  huart4.Init.Mode = UART_MODE_TX_RX;
  huart4.Init.HwFlowCtl = UART_HWCONTROL_NONE;
  huart4.Init.OverSampling = UART_OVERSAMPLING_16;
  huart4.Init.OneBitSampling = UART_ONE_BIT_SAMPLE_DISABLE;
  huart4.Init.ClockPrescaler = UART_PRESCALER_DIV1;
  huart4.AdvancedInit.AdvFeatureInit = UART_ADVFEATURE_NO_INIT;
  if (HAL_UART_Init(&huart4) != HAL_OK)
  {
    Error_Handler();
  }
  if (HAL_UARTEx_SetTxFifoThreshold(&huart4, UART_TXFIFO_THRESHOLD_1_8) != HAL_OK)
  {
    Error_Handler();
  }
  if (HAL_UARTEx_SetRxFifoThreshold(&huart4, UART_RXFIFO_THRESHOLD_1_8) != HAL_OK)
  {
    Error_Handler();
  }
  if (HAL_UARTEx_DisableFifoMode(&huart4) != HAL_OK)
  {
    Error_Handler();
  }

}

static void MX_UART5_Init(void)
{

  huart5.Instance = UART5;
  huart5.Init.BaudRate = 460800;
  huart5.Init.WordLength = UART_WORDLENGTH_8B;
  huart5.Init.StopBits = UART_STOPBITS_1;
  huart5.Init.Parity = UART_PARITY_NONE;
  huart5.Init.Mode = UART_MODE_TX_RX;
  huart5.Init.HwFlowCtl = UART_HWCONTROL_NONE;
  huart5.Init.OverSampling = UART_OVERSAMPLING_16;
  huart5.Init.OneBitSampling = UART_ONE_BIT_SAMPLE_DISABLE;
  huart5.Init.ClockPrescaler = UART_PRESCALER_DIV1;
  huart5.AdvancedInit.AdvFeatureInit = UART_ADVFEATURE_NO_INIT;
  if (HAL_UART_Init(&huart5) != HAL_OK)
  {
    Error_Handler();
  }
  if (HAL_UARTEx_SetTxFifoThreshold(&huart5, UART_TXFIFO_THRESHOLD_1_8) != HAL_OK)
  {
    Error_Handler();
  }
  if (HAL_UARTEx_SetRxFifoThreshold(&huart5, UART_RXFIFO_THRESHOLD_1_8) != HAL_OK)
  {
    Error_Handler();
  }
  if (HAL_UARTEx_DisableFifoMode(&huart5) != HAL_OK)
  {
    Error_Handler();
  }

}

static void MX_UART7_Init(void)
{

  huart7.Instance = UART7;
  huart7.Init.BaudRate = 1000000;
  huart7.Init.WordLength = UART_WORDLENGTH_8B;
  huart7.Init.StopBits = UART_STOPBITS_1;
  huart7.Init.Parity = UART_PARITY_NONE;
  huart7.Init.Mode = UART_MODE_TX_RX;
  huart7.Init.HwFlowCtl = UART_HWCONTROL_NONE;
  huart7.Init.OverSampling = UART_OVERSAMPLING_16;
  huart7.Init.OneBitSampling = UART_ONE_BIT_SAMPLE_DISABLE;
  huart7.Init.ClockPrescaler = UART_PRESCALER_DIV1;
  huart7.AdvancedInit.AdvFeatureInit = UART_ADVFEATURE_NO_INIT;
  if (HAL_UART_Init(&huart7) != HAL_OK)
  {
    Error_Handler();
  }
  if (HAL_UARTEx_SetTxFifoThreshold(&huart7, UART_TXFIFO_THRESHOLD_1_8) != HAL_OK)
  {
    Error_Handler();
  }
  if (HAL_UARTEx_SetRxFifoThreshold(&huart7, UART_RXFIFO_THRESHOLD_1_8) != HAL_OK)
  {
    Error_Handler();
  }
  if (HAL_UARTEx_DisableFifoMode(&huart7) != HAL_OK)
  {
    Error_Handler();
  }

}

static void MX_UART9_Init(void)
{

  huart9.Instance = UART9;
  huart9.Init.BaudRate = 460800;
  huart9.Init.WordLength = UART_WORDLENGTH_8B;
  huart9.Init.StopBits = UART_STOPBITS_1;
  huart9.Init.Parity = UART_PARITY_NONE;
  huart9.Init.Mode = UART_MODE_TX_RX;
  huart9.Init.HwFlowCtl = UART_HWCONTROL_NONE;
  huart9.Init.OverSampling = UART_OVERSAMPLING_16;
  huart9.Init.OneBitSampling = UART_ONE_BIT_SAMPLE_DISABLE;
  huart9.Init.ClockPrescaler = UART_PRESCALER_DIV1;
  huart9.AdvancedInit.AdvFeatureInit = UART_ADVFEATURE_NO_INIT;
  if (HAL_UART_Init(&huart9) != HAL_OK)
  {
    Error_Handler();
  }
  if (HAL_UARTEx_SetTxFifoThreshold(&huart9, UART_TXFIFO_THRESHOLD_1_8) != HAL_OK)
  {
    Error_Handler();
  }
  if (HAL_UARTEx_SetRxFifoThreshold(&huart9, UART_RXFIFO_THRESHOLD_1_8) != HAL_OK)
  {
    Error_Handler();
  }
  if (HAL_UARTEx_DisableFifoMode(&huart9) != HAL_OK)
  {
    Error_Handler();
  }

}

static void MX_USART2_UART_Init(void)
{

  huart2.Instance = USART2;
  huart2.Init.BaudRate = 1000000;
  huart2.Init.WordLength = UART_WORDLENGTH_8B;
  huart2.Init.StopBits = UART_STOPBITS_1;
  huart2.Init.Parity = UART_PARITY_NONE;
  huart2.Init.Mode = UART_MODE_TX_RX;
  huart2.Init.HwFlowCtl = UART_HWCONTROL_NONE;
  huart2.Init.OverSampling = UART_OVERSAMPLING_16;
  huart2.Init.OneBitSampling = UART_ONE_BIT_SAMPLE_DISABLE;
  huart2.Init.ClockPrescaler = UART_PRESCALER_DIV1;
  huart2.AdvancedInit.AdvFeatureInit = UART_ADVFEATURE_NO_INIT;
  if (HAL_UART_Init(&huart2) != HAL_OK)
  {
    Error_Handler();
  }
  if (HAL_UARTEx_SetTxFifoThreshold(&huart2, UART_TXFIFO_THRESHOLD_1_8) != HAL_OK)
  {
    Error_Handler();
  }
  if (HAL_UARTEx_SetRxFifoThreshold(&huart2, UART_RXFIFO_THRESHOLD_1_8) != HAL_OK)
  {
    Error_Handler();
  }
  if (HAL_UARTEx_DisableFifoMode(&huart2) != HAL_OK)
  {
    Error_Handler();
  }

}

static void MX_USART3_UART_Init(void)
{

  huart3.Instance = USART3;
  huart3.Init.BaudRate = 115200;
  huart3.Init.WordLength = UART_WORDLENGTH_8B;
  huart3.Init.StopBits = UART_STOPBITS_1;
  huart3.Init.Parity = UART_PARITY_NONE;
  huart3.Init.Mode = UART_MODE_TX_RX;
  huart3.Init.HwFlowCtl = UART_HWCONTROL_NONE;
  huart3.Init.OverSampling = UART_OVERSAMPLING_16;
  huart3.Init.OneBitSampling = UART_ONE_BIT_SAMPLE_DISABLE;
  huart3.Init.ClockPrescaler = UART_PRESCALER_DIV1;
  huart3.AdvancedInit.AdvFeatureInit = UART_ADVFEATURE_NO_INIT;
  if (HAL_UART_Init(&huart3) != HAL_OK)
  {
    Error_Handler();
  }
  if (HAL_UARTEx_SetTxFifoThreshold(&huart3, UART_TXFIFO_THRESHOLD_1_8) != HAL_OK)
  {
    Error_Handler();
  }
  if (HAL_UARTEx_SetRxFifoThreshold(&huart3, UART_RXFIFO_THRESHOLD_1_8) != HAL_OK)
  {
    Error_Handler();
  }
  if (HAL_UARTEx_DisableFifoMode(&huart3) != HAL_OK)
  {
    Error_Handler();
  }

}

static void MX_USB_OTG_HS_USB_Init(void)
{

}

static void MX_DMA_Init(void)
{

  /* DMA controller clock enable */
  __HAL_RCC_DMA1_CLK_ENABLE();

  /* DMA interrupt init */
  /* DMA1_Stream0_IRQn interrupt configuration */
  HAL_NVIC_SetPriority(DMA1_Stream0_IRQn, 0, 0);
  HAL_NVIC_EnableIRQ(DMA1_Stream0_IRQn);
  /* DMA1_Stream1_IRQn interrupt configuration */
  HAL_NVIC_SetPriority(DMA1_Stream1_IRQn, 0, 0);
  HAL_NVIC_EnableIRQ(DMA1_Stream1_IRQn);
  /* DMA1_Stream2_IRQn interrupt configuration */
  HAL_NVIC_SetPriority(DMA1_Stream2_IRQn, 0, 0);
  HAL_NVIC_EnableIRQ(DMA1_Stream2_IRQn);
  /* DMA1_Stream3_IRQn interrupt configuration */
  HAL_NVIC_SetPriority(DMA1_Stream3_IRQn, 0, 0);
  HAL_NVIC_EnableIRQ(DMA1_Stream3_IRQn);

}

static void MX_GPIO_Init(void)
{
  GPIO_InitTypeDef GPIO_InitStruct = {0};

  /* GPIO Ports Clock Enable */
  __HAL_RCC_GPIOE_CLK_ENABLE();
  __HAL_RCC_GPIOC_CLK_ENABLE();
  __HAL_RCC_GPIOF_CLK_ENABLE();
  __HAL_RCC_GPIOH_CLK_ENABLE();
  __HAL_RCC_GPIOA_CLK_ENABLE();
  __HAL_RCC_GPIOB_CLK_ENABLE();
  __HAL_RCC_GPIOG_CLK_ENABLE();
  __HAL_RCC_GPIOD_CLK_ENABLE();

  /*Configure GPIO pin Output Level */
  HAL_GPIO_WritePin(GPIOF, EN3_Pin|DIR2_Pin|EN2_Pin, GPIO_PIN_RESET);

  /*Configure GPIO pin Output Level */
  HAL_GPIO_WritePin(GPIOA, NXT1_Pin|NXT3_Pin, GPIO_PIN_RESET);

  /*Configure GPIO pin Output Level */
  HAL_GPIO_WritePin(GPIOB, LED_GREEN_Pin|EN1_Pin|LED_RED_Pin, GPIO_PIN_RESET);

  /*Configure GPIO pin Output Level */
  HAL_GPIO_WritePin(GPIOD, GPIO_PIN_10, GPIO_PIN_RESET);

  /*Configure GPIO pin Output Level */
  HAL_GPIO_WritePin(GPIOG, DIR1_Pin|NXT2_Pin, GPIO_PIN_RESET);

  /*Configure GPIO pin Output Level */
  HAL_GPIO_WritePin(DIR3_GPIO_Port, DIR3_Pin, GPIO_PIN_RESET);

  /*Configure GPIO pin Output Level */
  HAL_GPIO_WritePin(LED_YELLOW_GPIO_Port, LED_YELLOW_Pin, GPIO_PIN_RESET);

  /*Configure GPIO pin : B1_Pin */
  GPIO_InitStruct.Pin = B1_Pin;
  GPIO_InitStruct.Mode = GPIO_MODE_INPUT;
  GPIO_InitStruct.Pull = GPIO_NOPULL;
  HAL_GPIO_Init(B1_GPIO_Port, &GPIO_InitStruct);

  /*Configure GPIO pins : EN3_Pin DIR2_Pin EN2_Pin */
  GPIO_InitStruct.Pin = EN3_Pin|DIR2_Pin|EN2_Pin;
  GPIO_InitStruct.Mode = GPIO_MODE_OUTPUT_PP;
  GPIO_InitStruct.Pull = GPIO_NOPULL;
  GPIO_InitStruct.Speed = GPIO_SPEED_FREQ_LOW;
  HAL_GPIO_Init(GPIOF, &GPIO_InitStruct);

  /*Configure GPIO pins : EXTA1_Pin EXTA2_Pin */
  GPIO_InitStruct.Pin = EXTA1_Pin|EXTA2_Pin;
  GPIO_InitStruct.Mode = GPIO_MODE_ANALOG;
  GPIO_InitStruct.Pull = GPIO_NOPULL;
  HAL_GPIO_Init(GPIOF, &GPIO_InitStruct);

  /*Configure GPIO pins : NXT1_Pin NXT3_Pin */
  GPIO_InitStruct.Pin = NXT1_Pin|NXT3_Pin;
  GPIO_InitStruct.Mode = GPIO_MODE_OUTPUT_PP;
  GPIO_InitStruct.Pull = GPIO_NOPULL;
  GPIO_InitStruct.Speed = GPIO_SPEED_FREQ_LOW;
  HAL_GPIO_Init(GPIOA, &GPIO_InitStruct);

  /*Configure GPIO pins : LED_GREEN_Pin EN1_Pin LED_RED_Pin */
  GPIO_InitStruct.Pin = LED_GREEN_Pin|EN1_Pin|LED_RED_Pin;
  GPIO_InitStruct.Mode = GPIO_MODE_OUTPUT_PP;
  GPIO_InitStruct.Pull = GPIO_NOPULL;
  GPIO_InitStruct.Speed = GPIO_SPEED_FREQ_LOW;
  HAL_GPIO_Init(GPIOB, &GPIO_InitStruct);

  /*Configure GPIO pins : FLIMIT1_Pin RLIMIT1_Pin RLIMIT2_Pin */
  GPIO_InitStruct.Pin = FLIMIT1_Pin|RLIMIT1_Pin|RLIMIT2_Pin;
  GPIO_InitStruct.Mode = GPIO_MODE_INPUT;
  GPIO_InitStruct.Pull = GPIO_NOPULL;
  HAL_GPIO_Init(GPIOE, &GPIO_InitStruct);

  /*Configure GPIO pins : FJOG3_Pin RJOG3_Pin RJOG1_Pin FJOG1_Pin */
  GPIO_InitStruct.Pin = FJOG3_Pin|RJOG3_Pin|RJOG1_Pin|FJOG1_Pin;
  GPIO_InitStruct.Mode = GPIO_MODE_INPUT;
  GPIO_InitStruct.Pull = GPIO_PULLUP;
  HAL_GPIO_Init(GPIOE, &GPIO_InitStruct);

  /*Configure GPIO pins : FJOG2_Pin RJOG2_Pin */
  GPIO_InitStruct.Pin = FJOG2_Pin|RJOG2_Pin;
  GPIO_InitStruct.Mode = GPIO_MODE_INPUT;
  GPIO_InitStruct.Pull = GPIO_PULLUP;
  HAL_GPIO_Init(GPIOB, &GPIO_InitStruct);

  /*Configure GPIO pins : FLIMIT3_Pin RLIMIT3_Pin */
  GPIO_InitStruct.Pin = FLIMIT3_Pin|RLIMIT3_Pin;
  GPIO_InitStruct.Mode = GPIO_MODE_INPUT;
  GPIO_InitStruct.Pull = GPIO_NOPULL;
  HAL_GPIO_Init(GPIOB, &GPIO_InitStruct);

  /*Configure GPIO pins : ENCI3_Pin DIAG2_Pin DIAG1_Pin DIAG3_Pin */
  GPIO_InitStruct.Pin = ENCI3_Pin|DIAG2_Pin|DIAG1_Pin|DIAG3_Pin;
  GPIO_InitStruct.Mode = GPIO_MODE_IT_RISING;
  GPIO_InitStruct.Pull = GPIO_NOPULL;
  HAL_GPIO_Init(GPIOB, &GPIO_InitStruct);

  /*Configure GPIO pin : PD10 */
  GPIO_InitStruct.Pin = GPIO_PIN_10;
  GPIO_InitStruct.Mode = GPIO_MODE_OUTPUT_PP;
  GPIO_InitStruct.Pull = GPIO_NOPULL;
  GPIO_InitStruct.Speed = GPIO_SPEED_FREQ_LOW;
  HAL_GPIO_Init(GPIOD, &GPIO_InitStruct);

  /*Configure GPIO pin : ENCI1_Pin */
  GPIO_InitStruct.Pin = ENCI1_Pin;
  GPIO_InitStruct.Mode = GPIO_MODE_INPUT;
  GPIO_InitStruct.Pull = GPIO_NOPULL;
  HAL_GPIO_Init(ENCI1_GPIO_Port, &GPIO_InitStruct);

  /*Configure GPIO pin : ENCI2_Pin */
  GPIO_InitStruct.Pin = ENCI2_Pin;
  GPIO_InitStruct.Mode = GPIO_MODE_IT_RISING;
  GPIO_InitStruct.Pull = GPIO_NOPULL;
  HAL_GPIO_Init(ENCI2_GPIO_Port, &GPIO_InitStruct);

  /*Configure GPIO pins : DIR1_Pin NXT2_Pin */
  GPIO_InitStruct.Pin = DIR1_Pin|NXT2_Pin;
  GPIO_InitStruct.Mode = GPIO_MODE_OUTPUT_PP;
  GPIO_InitStruct.Pull = GPIO_NOPULL;
  GPIO_InitStruct.Speed = GPIO_SPEED_FREQ_LOW;
  HAL_GPIO_Init(GPIOG, &GPIO_InitStruct);

  /*Configure GPIO pin : DIR3_Pin */
  GPIO_InitStruct.Pin = DIR3_Pin;
  GPIO_InitStruct.Mode = GPIO_MODE_OUTPUT_PP;
  GPIO_InitStruct.Pull = GPIO_NOPULL;
  GPIO_InitStruct.Speed = GPIO_SPEED_FREQ_LOW;
  HAL_GPIO_Init(DIR3_GPIO_Port, &GPIO_InitStruct);

  /*Configure GPIO pin : USB_FS_VBUS_Pin */
  GPIO_InitStruct.Pin = USB_FS_VBUS_Pin;
  GPIO_InitStruct.Mode = GPIO_MODE_INPUT;
  GPIO_InitStruct.Pull = GPIO_NOPULL;
  HAL_GPIO_Init(USB_FS_VBUS_GPIO_Port, &GPIO_InitStruct);

  /*Configure GPIO pin : USB_FS_ID_Pin */
  GPIO_InitStruct.Pin = USB_FS_ID_Pin;
  GPIO_InitStruct.Mode = GPIO_MODE_AF_PP;
  GPIO_InitStruct.Pull = GPIO_NOPULL;
  GPIO_InitStruct.Speed = GPIO_SPEED_FREQ_LOW;
  GPIO_InitStruct.Alternate = GPIO_AF10_OTG1_HS;
  HAL_GPIO_Init(USB_FS_ID_GPIO_Port, &GPIO_InitStruct);

  /*Configure GPIO pin : FLIMIT2_Pin */
  GPIO_InitStruct.Pin = FLIMIT2_Pin;
  GPIO_InitStruct.Mode = GPIO_MODE_INPUT;
  GPIO_InitStruct.Pull = GPIO_NOPULL;
  HAL_GPIO_Init(FLIMIT2_GPIO_Port, &GPIO_InitStruct);

  /*Configure GPIO pin : LED_YELLOW_Pin */
  GPIO_InitStruct.Pin = LED_YELLOW_Pin;
  GPIO_InitStruct.Mode = GPIO_MODE_OUTPUT_PP;
  GPIO_InitStruct.Pull = GPIO_NOPULL;
  GPIO_InitStruct.Speed = GPIO_SPEED_FREQ_LOW;
  HAL_GPIO_Init(LED_YELLOW_GPIO_Port, &GPIO_InitStruct);

}

void Error_Handler(void)
{
  __disable_irq();
  while (1)
  {
  }
}
